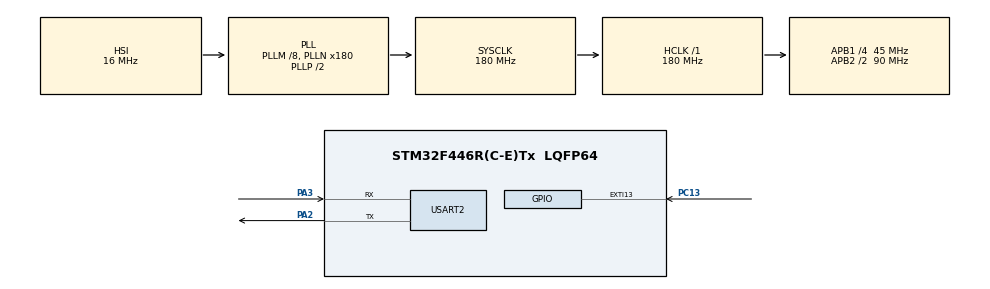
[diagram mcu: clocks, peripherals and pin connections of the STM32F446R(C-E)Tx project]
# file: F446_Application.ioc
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Mcu.Family=STM32F4
Mcu.Name=STM32F446R(C-E)Tx
Mcu.Package=LQFP64
NVIC.EXTI15_10_IRQn=true\:0\:0\:false\:false\:true\:true\:true\:true
NVIC.PriorityGroup=NVIC_PRIORITYGROUP_4
PA2.Mode=Asynchronous
PA2.Signal=USART2_TX
PA3.Mode=Asynchronous
PA3.Signal=USART2_RX
PC13.GPIO_ModeDefaultEXTI=GPIO_MODE_IT_FALLING
PC13.GPIO_PuPd=GPIO_PULLUP
PC13.Signal=GPXTI13
PH0-OSC_IN.Mode=HSE-External-Clock-Source
PH0-OSC_IN.Signal=RCC_OSC_IN
PH1-OSC_OUT.Mode=HSE-External-Clock-Source
PH1-OSC_OUT.Signal=RCC_OSC_OUT
ProjectManager.HeapSize=0x200
ProjectManager.StackSize=0x400
ProjectManager.TargetToolchain=STM32CubeIDE
RCC.AHBFreq_Value=180000000
RCC.APB1CLKDivider=RCC_HCLK_DIV4
RCC.APB1Freq_Value=45000000
RCC.APB1TimFreq_Value=90000000
RCC.APB2CLKDivider=RCC_HCLK_DIV2
RCC.APB2Freq_Value=90000000
RCC.APB2TimFreq_Value=180000000
RCC.CortexFreq_Value=180000000
RCC.HCLKFreq_Value=180000000
RCC.HSE_VALUE=8000000
RCC.PLLM=8
RCC.PLLN=180
RCC.SYSCLKFreq_VALUE=180000000
RCC.SYSCLKSource=RCC_SYSCLKSOURCE_PLLCLK
RCC.USBFreq_Value=180000000
RCC.VCOOutputFreq_Value=360000000
USART2.VirtualMode=VM_ASYNC
board=custom

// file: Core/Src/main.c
/* USER CODE BEGIN Header */
/**
  ******************************************************************************
  * @file           : main.c
  * @brief          : Main program body
  ******************************************************************************
  * @attention
  *
  * Copyright (c) 2025 STMicroelectronics.
  * All rights reserved.
  *
  * This software is licensed under terms that can be found in the LICENSE file
  * in the root directory of this software component.
  * If no LICENSE file comes with this software, it is provided AS-IS.
  *
  ******************************************************************************
  */
/* USER CODE END Header */
#include "main.h"

/* USER CODE BEGIN Includes */
#include "flash_layout.h"
#include "string.h"
#include "app_header.h"
#include "app_ota.h"
/* USER CODE END Includes */

UART_HandleTypeDef huart2;

void SystemClock_Config(void);
static void MX_GPIO_Init(void);
static void MX_USART2_UART_Init(void);

/* USER CODE BEGIN 0 */

__attribute__((section(".header"))) const app_header_t app_header =
{
	.ota_flag = 0,
    .magic   = 0xABCDEFAB,
    .size    = 11468,
    .crc     = 0xC683C39A,
    .version = 0
};

volatile int isButtonPressed = 0;

void HAL_GPIO_EXTI_Callback(uint16_t GPIO_Pin)
{
	isButtonPressed = 1;
}

/* USER CODE END 0 */

int main(void)
{

  /* MCU Configuration--------------------------------------------------------*/

  /* Reset of all peripherals, Initializes the Flash interface and the Systick. */
  HAL_Init();

  /* USER CODE BEGIN Init */

  SCB->VTOR = APP_START_ADDR;
  __enable_irq();

  /* USER CODE END Init */

  /* Configure the system clock */
  SystemClock_Config();

  /* Initialize all configured peripherals */
  MX_GPIO_Init();
  MX_USART2_UART_Init();
  /* USER CODE BEGIN 2 */

  char data[] = "Inside Application!!\r\n";
  HAL_UART_Transmit(&huart2, (uint8_t *)data, strlen(data), 1000);

  /* USER CODE END 2 */

  /* Infinite loop */
  while (1)
  {

    /* USER CODE BEGIN 3 */

	  HAL_GPIO_TogglePin(GPIOA, GPIO_PIN_5);
	  HAL_Delay(1000);

	  if (isButtonPressed == 1)
	  {
		  HAL_Delay(250);
		  enable_ota_request();
	  }
  }
  /* USER CODE END 3 */
}

void SystemClock_Config(void)
{
  RCC_OscInitTypeDef RCC_OscInitStruct = {0};
  RCC_ClkInitTypeDef RCC_ClkInitStruct = {0};

  /** Configure the main internal regulator output voltage
  */
  __HAL_RCC_PWR_CLK_ENABLE();
  __HAL_PWR_VOLTAGESCALING_CONFIG(PWR_REGULATOR_VOLTAGE_SCALE1);

  /** Initializes the RCC Oscillators according to the specified parameters
  * in the RCC_OscInitTypeDef structure.
  */
  RCC_OscInitStruct.OscillatorType = RCC_OSCILLATORTYPE_HSI;
  RCC_OscInitStruct.HSIState = RCC_HSI_ON;
  RCC_OscInitStruct.HSICalibrationValue = RCC_HSICALIBRATION_DEFAULT;
  RCC_OscInitStruct.PLL.PLLState = RCC_PLL_ON;
  RCC_OscInitStruct.PLL.PLLSource = RCC_PLLSOURCE_HSI;
  RCC_OscInitStruct.PLL.PLLM = 8;
  RCC_OscInitStruct.PLL.PLLN = 180;
  RCC_OscInitStruct.PLL.PLLP = RCC_PLLP_DIV2;
  RCC_OscInitStruct.PLL.PLLQ = 2;
  RCC_OscInitStruct.PLL.PLLR = 2;
  if (HAL_RCC_OscConfig(&RCC_OscInitStruct) != HAL_OK)
  {
    Error_Handler();
  }

  /** Activate the Over-Drive mode
  */
  if (HAL_PWREx_EnableOverDrive() != HAL_OK)
  {
    Error_Handler();
  }

  /** Initializes the CPU, AHB and APB buses clocks
  */
  RCC_ClkInitStruct.ClockType = RCC_CLOCKTYPE_HCLK|RCC_CLOCKTYPE_SYSCLK
                              |RCC_CLOCKTYPE_PCLK1|RCC_CLOCKTYPE_PCLK2;
  RCC_ClkInitStruct.SYSCLKSource = RCC_SYSCLKSOURCE_PLLCLK;
  RCC_ClkInitStruct.AHBCLKDivider = RCC_SYSCLK_DIV1;
  RCC_ClkInitStruct.APB1CLKDivider = RCC_HCLK_DIV4;
  RCC_ClkInitStruct.APB2CLKDivider = RCC_HCLK_DIV2;

  if (HAL_RCC_ClockConfig(&RCC_ClkInitStruct, FLASH_LATENCY_5) != HAL_OK)
  {
    Error_Handler();
  }
}

static void MX_USART2_UART_Init(void)
{

  huart2.Instance = USART2;
  huart2.Init.BaudRate = 115200;
  huart2.Init.WordLength = UART_WORDLENGTH_8B;
  huart2.Init.StopBits = UART_STOPBITS_1;
  huart2.Init.Parity = UART_PARITY_NONE;
  huart2.Init.Mode = UART_MODE_TX_RX;
  huart2.Init.HwFlowCtl = UART_HWCONTROL_NONE;
  huart2.Init.OverSampling = UART_OVERSAMPLING_16;
  if (HAL_UART_Init(&huart2) != HAL_OK)
  {
    Error_Handler();
  }

}

static void MX_GPIO_Init(void)
{
  GPIO_InitTypeDef GPIO_InitStruct = {0};

  /* GPIO Ports Clock Enable */
  __HAL_RCC_GPIOC_CLK_ENABLE();
  __HAL_RCC_GPIOH_CLK_ENABLE();
  __HAL_RCC_GPIOA_CLK_ENABLE();

  /*Configure GPIO pin : PC13 */
  GPIO_InitStruct.Pin = GPIO_PIN_13;
  GPIO_InitStruct.Mode = GPIO_MODE_IT_FALLING;
  GPIO_InitStruct.Pull = GPIO_PULLUP;
  HAL_GPIO_Init(GPIOC, &GPIO_InitStruct);

  /* EXTI interrupt init*/
  HAL_NVIC_SetPriority(EXTI15_10_IRQn, 0, 0);
  HAL_NVIC_EnableIRQ(EXTI15_10_IRQn);

}

void Error_Handler(void)
{
  __disable_irq();
  while (1)
  {
  }
}
